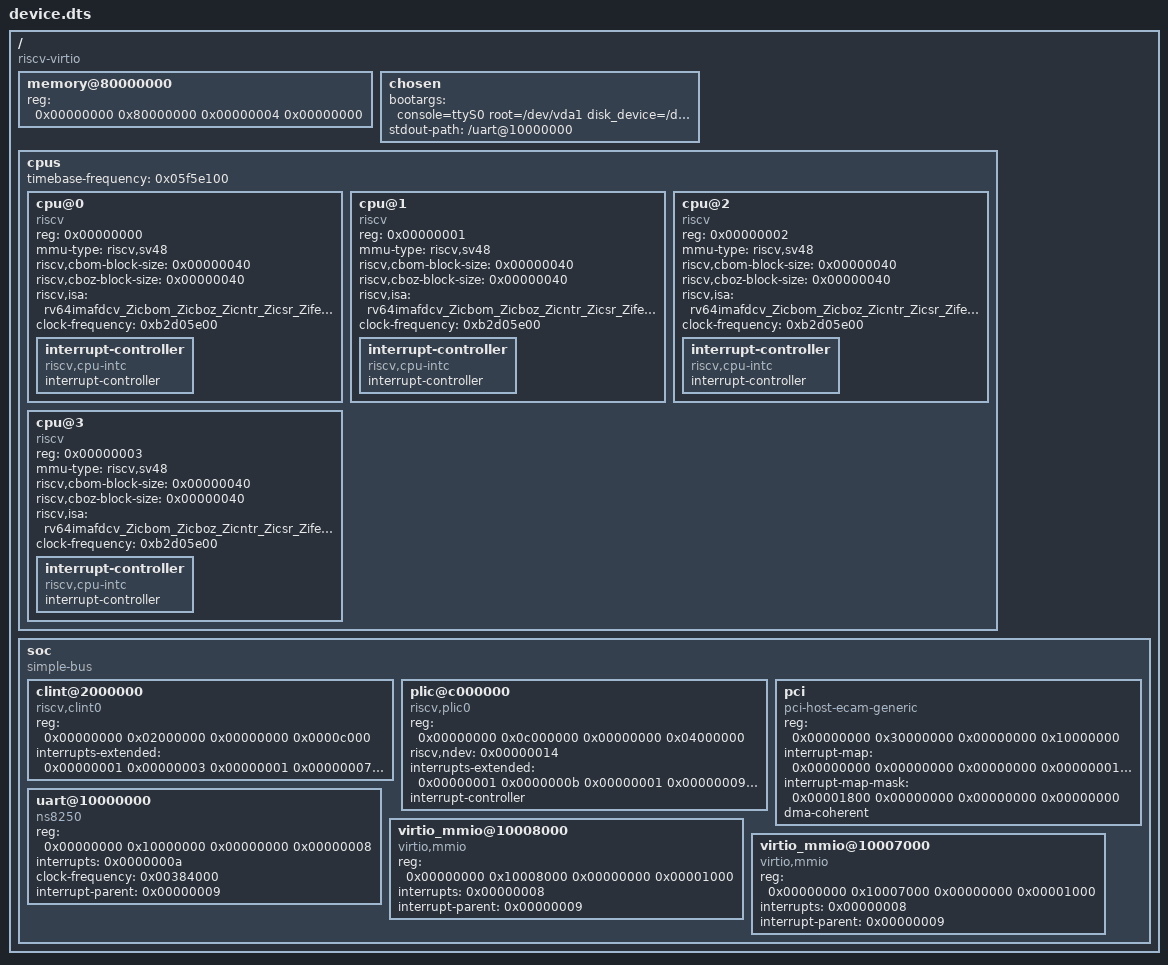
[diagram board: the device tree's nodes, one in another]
/dts-v1/;
// version:		17
// last_comp_version:	16
// boot_cpuid_phys:	0x0

/ {
    #address-cells = <0x00000002>;
    #size-cells = <0x00000002>;
    compatible = "riscv-virtio";
    memory@80000000 {
        device_type = "memory";
        reg = <0x00000000 0x80000000 0x00000004 0x00000000>;
    };
    chosen {
        bootargs = "console=ttyS0 root=/dev/vda1 disk_device=/dev/vda1 rw";
        stdout-path = "/uart@10000000";
    };
    cpus {
        #address-cells = <0x00000001>;
        #size-cells = <0x00000000>;
        timebase-frequency = <0x05f5e100>;
        cpu@0 {
            device_type = "cpu";
            reg = <0x00000000>;
            mmu-type = "riscv,sv48";
            riscv,cbom-block-size = <0x00000040>;
            riscv,cboz-block-size = <0x00000040>;
            status = "okay";
            riscv,isa = "rv64imafdcv_Zicbom_Zicboz_Zicntr_Zicsr_Zifencei_Zihpm_Zba_Zbb_Zbs";
            clock-frequency = <0xb2d05e00>;
            compatible = "riscv";
            phandle = <0x00000002>;
            interrupt-controller {
                #interrupt-cells = <0x00000001>;
                interrupt-controller;
                compatible = "riscv,cpu-intc";
                phandle = <0x00000001>;
            };
        };
        cpu@1 {
            device_type = "cpu";
            reg = <0x00000001>;
            mmu-type = "riscv,sv48";
            riscv,cbom-block-size = <0x00000040>;
            riscv,cboz-block-size = <0x00000040>;
            status = "okay";
            riscv,isa = "rv64imafdcv_Zicbom_Zicboz_Zicntr_Zicsr_Zifencei_Zihpm_Zba_Zbb_Zbs";
            clock-frequency = <0xb2d05e00>;
            compatible = "riscv";
            phandle = <0x00000004>;
            interrupt-controller {
                #interrupt-cells = <0x00000001>;
                interrupt-controller;
                compatible = "riscv,cpu-intc";
                phandle = <0x00000003>;
            };
        };
        cpu@2 {
            device_type = "cpu";
            reg = <0x00000002>;
            mmu-type = "riscv,sv48";
            riscv,cbom-block-size = <0x00000040>;
            riscv,cboz-block-size = <0x00000040>;
            status = "okay";
            riscv,isa = "rv64imafdcv_Zicbom_Zicboz_Zicntr_Zicsr_Zifencei_Zihpm_Zba_Zbb_Zbs";
            clock-frequency = <0xb2d05e00>;
            compatible = "riscv";
            phandle = <0x00000006>;
            interrupt-controller {
                #interrupt-cells = <0x00000001>;
                interrupt-controller;
                compatible = "riscv,cpu-intc";
                phandle = <0x00000005>;
            };
        };
        cpu@3 {
            device_type = "cpu";
            reg = <0x00000003>;
            mmu-type = "riscv,sv48";
            riscv,cbom-block-size = <0x00000040>;
            riscv,cboz-block-size = <0x00000040>;
            status = "okay";
            riscv,isa = "rv64imafdcv_Zicbom_Zicboz_Zicntr_Zicsr_Zifencei_Zihpm_Zba_Zbb_Zbs";
            clock-frequency = <0xb2d05e00>;
            compatible = "riscv";
            phandle = <0x00000008>;
            interrupt-controller {
                #interrupt-cells = <0x00000001>;
                interrupt-controller;
                compatible = "riscv,cpu-intc";
                phandle = <0x00000007>;
            };
        };
    };
    soc {
        #address-cells = <0x00000002>;
        #size-cells = <0x00000002>;
        ranges;
        compatible = "simple-bus";
        clint@2000000 {
            reg = <0x00000000 0x02000000 0x00000000 0x0000c000>;
            interrupts-extended = <0x00000001 0x00000003 0x00000001 0x00000007 0x00000003 0x00000003 0x00000003 0x00000007 0x00000005 0x00000003 0x00000005 0x00000007 0x00000007 0x00000003 0x00000007 0x00000007>;
            compatible = "riscv,clint0";
        };
        plic@c000000 {
            reg = <0x00000000 0x0c000000 0x00000000 0x04000000>;
            #address-cells = <0x00000000>;
            #interrupt-cells = <0x00000001>;
            phandle = <0x00000009>;
            riscv,ndev = <0x00000014>;
            interrupts-extended = <0x00000001 0x0000000b 0x00000001 0x00000009 0x00000003 0x0000000b 0x00000003 0x00000009 0x00000005 0x0000000b 0x00000005 0x00000009 0x00000007 0x0000000b 0x00000007 0x00000009>;
            interrupt-controller;
            compatible = "riscv,plic0";
        };
        pci {
            compatible = "pci-host-ecam-generic";
            device_type = "pci";
            #address-cells = <0x00000003>;
            #size-cells = <0x00000002>;
            #interrupt-cells = <0x00000001>;
            reg = <0x00000000 0x30000000 0x00000000 0x10000000>;
            ranges = <0x01000000 0x00000000 0x00000000 0x00000000 0x2f000000 0x00000000 0x00010000 0x02000000 0x00000000 0x00000000 0x00000000 0x40000000 0x00000000 0x40000000>;
            interrupt-map = <0x00000000 0x00000000 0x00000000 0x00000001 0x00000009 0x00000010 0x00000800 0x00000000 0x00000000 0x00000002 0x00000009 0x00000011 0x00001000 0x00000000 0x00000000 0x00000003 0x00000009 0x00000012 0x00001800 0x00000000 0x00000000 0x00000004 0x00000009 0x00000013>;
            interrupt-map-mask = <0x00001800 0x00000000 0x00000000 0x00000000>;
            dma-coherent;
        };
        uart@10000000 {
            reg = <0x00000000 0x10000000 0x00000000 0x00000008>;
            interrupts = <0x0000000a>;
            clock-frequency = <0x00384000>;
            interrupt-parent = <0x00000009>;
            compatible = "ns8250", "ns16550a";
        };
        virtio_mmio@10008000 {
            reg = <0x00000000 0x10008000 0x00000000 0x00001000>;
            interrupts = <0x00000008>;
            interrupt-parent = <0x00000009>;
            compatible = "virtio,mmio";
        };
        virtio_mmio@10007000 {
            reg = <0x00000000 0x10007000 0x00000000 0x00001000>;
            interrupts = <0x00000008>;
            interrupt-parent = <0x00000009>;
            compatible = "virtio,mmio";
        };
    };
};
